# EFR32BG22C224F512GM32 register map
Vendor: Silicon Labs; Series: EFR32; File version: C
Registers are 32-bit, read-write, reset 0x0 unless marked. A register's access mark holds for its fields unless they carry their own. Offsets are from the block's base; [hi:lo] are bit positions; {n}, {i} and the like mark numbered series.

## CRYPTOACC_S_RNGCTRL — CRYPTOACC_S_RNGCTRL Registers
Base 0x4C021000
Same registers: CRYPTOACC_NS_RNGCTRL 0x5C021000
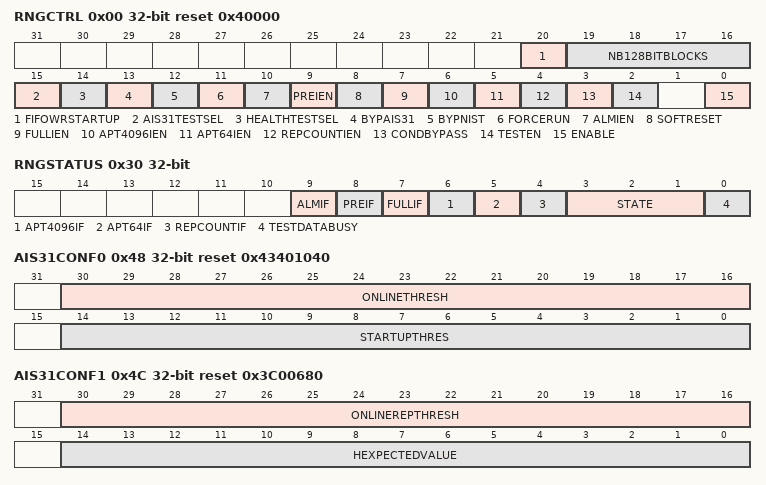
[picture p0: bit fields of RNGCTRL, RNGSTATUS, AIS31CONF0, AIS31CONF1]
0x00 RNGCTRL reset 0x40000
  [20] FIFOWRSTARTUP — Fifo Write Start Up
  [19:16] NB128BITBLOCKS — Number of 128b blocks in AES-CBCMAC
  [15] AIS31TESTSEL — AIS31 test input select
    0=BEFORE (Before conditioning); 1=AFTER (After conditioning)
  [14] HEALTHTESTSEL — Health test input select
    0=BEFORE (Before conditioning); 1=AFTER (After conditioning)
  [13] BYPAIS31 — AIS31 Start-up Test Bypass.
    0=NORMAL (AIS31 startup test is applied. No data will be written to the FIFO until the test passes.); 1=BYPASS (AIS31 startup test is bypassed.)
  [12] BYPNIST — NIST Start-up Test Bypass.
    0=NORMAL (NIST-800-90B startup test is applied. No data will be written to the FIFO until the test passes.); 1=BYPASS (NIST-800-90B startup test is bypassed.)
  [11] FORCERUN — Oscillator Force Run
    0=NORMAL (Oscillators will shut down when FIFO is full); 1=RUN (Oscillators will continue to run even after FIFO is full)
  [10] ALMIEN — IRQ enable for AIS31 noise alarm
  [9] PREIEN — IRQ enable for AIS31 prelim. noise alarm
  [8] SOFTRESET — Software Reset
    0=NORMAL (Module not in reset); 1=RESET (The continuous test, the conditioning function and the FIFO are reset)
  [7] FULLIEN — IRQ enable for FIFO full
  [6] APT4096IEN — IRQ enable for APT4096IF
  [5] APT64IEN — IRQ enable for APT64IF
  [4] REPCOUNTIEN — IRQ enable for Repetition Count Test
  [3] CONDBYPASS — Conditioning Bypass
    0=NORMAL (The conditionig function is used); 1=BYPASS (The conditioning function is bypassed)
  [2] TESTEN — Test Enable
    0=NOISE (Non-determinsitc random number generation); 1=TESTDATA (Pseudo-random number generation)
  [0] ENABLE — TRNG Module Enable
    0=DISABLED (Module disabled); 1=ENABLED (Module enabled)
0x04 FIFOLEVEL ro — Number of 32 bits words of random available in the FIFO. Writing to this register clears the FIFO full interrupt
0x08 FIFOTHRESH ro reset 0x3F — FIFO level at which the rings are restarted when in the FIFOFull_Off state, expressed in number of 128bit blocks
  [31:0] FIFOTHRESH — FIFO threshold level
0x0C FIFODEPTH ro reset 0x40 — Maximum number of 32 bits words that can be stored in the FIFO: 2^g_fifodepth
{0x10+4i} KEY{i} (i=0..3) — This set of registers bits form the 128-bit AES key used for conditioning function. The first byte (MSB of 128-bit word) is at address 0x0010, the second byte at address 0x0011...
  [31:0] KEY
0x20 TESTDATA wo — This register is used to feed known data to the conditioning function or to the continuous tests. See manual
  [31:0] VALUE — Test data input to conditioning tests
0x30 RNGSTATUS
  [9] ALMIF ro — AIS31 Noise Alarm interrupt status
  [8] PREIF — AIS31 Preliminary Noise Alarm IF
  [7] FULLIF ro — FIFO full interrupt status
  [6] APT4096IF ro — 4096-sample window Adaptive Prop. IF
  [5] APT64IF ro — 64-sample window Adaptive Proportion IF
  [4] REPCOUNTIF ro — Repetition Count Test interrupt status
  [3:1] STATE ro — State of the control FSM
    0=RESET (RESET State); 1=STARTUP (STARTUP State); 2=FIFOFULLON (FIFOFULLON State); 3=FIFOFULLOFF (FIFOFULLOFF State); 4=RUNNING (RUNNING State); 5=ERROR (ERROR State)
  [0] TESTDATABUSY ro
    0=IDLE (TESTDATA write is finished processing or no test in progress.); 1=BUSY (TESTDATA write is still being processed.)
0x34 INITWAITVAL reset 0xFFFF
  [15:0] INITWAITVAL — Wait counter value
0x40 SWOFFTMRVAL reset 0xFFFF — Number of clk cycles to wait before stopping the rings after the FIFO is full
  [15:0] SWOFFTMRVAL — Switch Off Timer Value
0x44 CLKDIV — Sample clock divider. The frequency at which the outputs of the rings are sampled is given by Fs = Fpclk/(ClkDiv + 1)
  [7:0] VALUE — Sample clock divider
0x48 AIS31CONF0 reset 0x43401040
  [30:16] ONLINETHRESH — Online Threshold
  [14:0] STARTUPTHRES — Start-up Threshold
0x4C AIS31CONF1 reset 0x3C00680
  [30:16] ONLINEREPTHRESH — Online Repeat Threshold
  [14:0] HEXPECTEDVALUE — Expected History Value
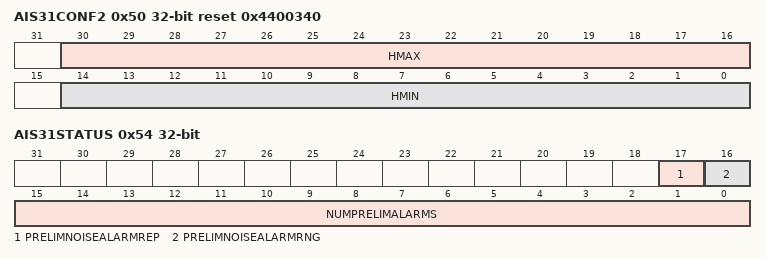
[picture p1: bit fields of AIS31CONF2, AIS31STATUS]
0x50 AIS31CONF2 reset 0x4400340
  [30:16] HMAX — Maximum Allowed History Value
  [14:0] HMIN — Minimum Allowed History Value
0x54 AIS31STATUS — This register is used to obtain diagnostic information about the AIS31 start-up and online tests when g_AIS31=True. Writing to this register clears all fields
  [17] PRELIMNOISEALARMREP — Preliminary noise alarm Rep
  [16] PRELIMNOISEALARMRNG — Preliminary noise alarm RNG
  [15:0] NUMPRELIMALARMS — Number of preliminary alarms
